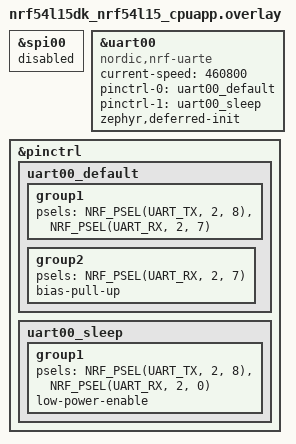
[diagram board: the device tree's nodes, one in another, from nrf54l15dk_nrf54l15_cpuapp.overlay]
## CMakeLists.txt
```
cmake_minimum_required(VERSION 3.20.0)
find_package(Zephyr REQUIRED HINTS $ENV{ZEPHYR_BASE})

project(54l15_uart_experiments_rx)

target_sources(app PRIVATE src/main.c)
```

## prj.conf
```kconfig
CONFIG_GPIO=y
CONFIG_SERIAL=y
CONFIG_UART_ASYNC_API=y
CONFIG_UART_NRFX=y
CONFIG_UART_00_ASYNC=y
```

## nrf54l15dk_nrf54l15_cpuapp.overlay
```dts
&spi00 {
	status = "disabled";
};

&uart00 {
    compatible = "nordic,nrf-uarte";
    status = "okay";
    current-speed = <460800>; // 14400 for 115.2, 460800 for 3686400
    pinctrl-0 = <&uart00_default>;
    pinctrl-1 = <&uart00_sleep>;
    pinctrl-names = "default", "sleep";
    //hw-flow-control;
    zephyr,deferred-init;
};

&pinctrl {
    uart00_default: uart00_default {
        group1 {
            psels = <NRF_PSEL(UART_TX, 2, 8)>,
                   <NRF_PSEL(UART_RX, 2, 7)>; // 2.0 need to cut SB16 (its connected to spif)
                //    <NRF_PSEL(UART_RTS, 2, 10)>,
                //    <NRF_PSEL(UART_CTS, 2, 9)>;
        };
        group2 {
            psels = <NRF_PSEL(UART_RX, 2, 7)>; // 2.7 LED2
                //    <NRF_PSEL(UART_CTS, 2, 9)>;
            bias-pull-up;
        };
    };

    uart00_sleep: uart00_sleep {
        group1 {
            psels = <NRF_PSEL(UART_TX, 2, 8)>,
                   <NRF_PSEL(UART_RX, 2, 0)>;
                //    <NRF_PSEL(UART_RTS, 2, 10)>,
                //    <NRF_PSEL(UART_CTS, 2, 9)>; // <-- 2 9 LED0>
            low-power-enable;
        };
    };
};
```

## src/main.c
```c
/*
 * Copyright (c) 2024 Nordic Semiconductor ASA
 * SPDX-License-Identifier: LicenseRef-Nordic-5-Clause
 */

/** @file
 *  @brief >1 Mbps testing w uart00 on nrf54l15 soc
 */
#include <zephyr/kernel.h>
#include <zephyr/kernel.h>
#include <zephyr/device.h>
#include <zephyr/devicetree.h>
#include <zephyr/drivers/gpio.h>
#include <zephyr/sys/printk.h>
#include <zephyr/drivers/uart.h>

#define SLEEP_TIME_MS 200
#define RECEIVE_BUF_SIZE 10
#define TRANSMIT_BUF_SIZE 8
#define RECEIVE_TIMEOUT 1000

#define TRANSMITTER true

const struct device *uart = DEVICE_DT_GET(DT_NODELABEL(uart00));
static uint8_t rx_buf[RECEIVE_BUF_SIZE] = {0};
static uint8_t tx_buf[TRANSMIT_BUF_SIZE] = {0x00, 0x0B, 0x0A, 0x0D, 0x0C, 0x00, 0x0D, 0x0E};
static void uart_cb(const struct device *dev, struct uart_event *evt, void *user_data)
{
        switch (evt->type)
        {
        case UART_TX_DONE:
                break;
        case UART_TX_ABORTED:
                break;
        case UART_RX_RDY:
                uart_tx(uart, evt->data.rx.buf, evt->data.rx.len, 2000);
                break;
        case UART_RX_BUF_REQUEST:
                break;
        case UART_RX_BUF_RELEASED:
                break;
        case UART_RX_DISABLED:
                uart_rx_enable(dev, rx_buf, sizeof rx_buf, RECEIVE_TIMEOUT);
                break;
        case UART_RX_STOPPED:
                break;
        default:
                break;
        }
}

int main(void)
{
        int ret = 0;
        ret =  device_init(uart);
        if(ret)
        {
                return 1; // unable to init
        }
        if (!device_is_ready(uart))
        {
                return 2; // dev not ready
        }
        ret = uart_callback_set(uart, uart_cb, NULL);
        if (ret)
        {
                return 3; // issue setting cb (check irq_conn)
        }
        uart_rx_enable(uart, rx_buf, sizeof rx_buf, RECEIVE_TIMEOUT);

        if (!TRANSMITTER)
        {
                ret = uart_tx(uart, tx_buf, sizeof(tx_buf), SYS_FOREVER_MS);
                k_msleep(10);
                while (1)
                {
                        k_yield();
                }
        }
        else
        {
                for(;;)
                {
                        ret = uart_tx(uart, tx_buf, sizeof(tx_buf), SYS_FOREVER_MS);
                        k_msleep(SLEEP_TIME_MS);
                }
        }

        return 0;
}
```
